# NUC2201AE_v1 register map
File version: 1.0
Registers are 32-bit, read-write, reset 0x0 unless marked. A register's access mark holds for its fields unless they carry their own. Offsets are from the block's base; [hi:lo] are bit positions; {n}, {i} and the like mark numbered series.

## GCR — GCR Register Map
Base 0x50000000
0x00 PDID ro reset 0x20140018 — Part Device Identification Number Register
  [31:0] PDID — Part Device Identification Number. This register reflects device part number code. Software can read this register to identify which device is used.
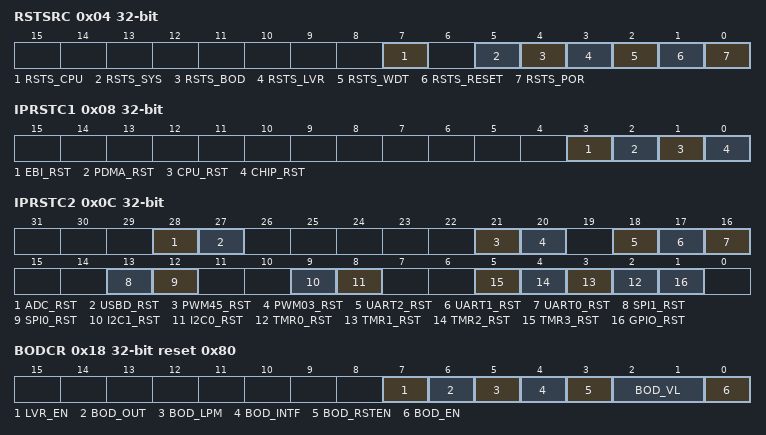
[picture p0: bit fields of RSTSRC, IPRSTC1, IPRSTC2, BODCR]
0x04 RSTSRC (reset mask 0xFFFFFF00) — System Reset Source Register
  [7] RSTS_CPU — CPU Reset Flag. The RSTS_CPU flag Is set by hardware if software writes CPU_RST (IPRSTC1[1]) 1 To reset Cortex-M0 kernel and flash memory controller (FMC). Note: Write 1 to clear this bit to 0.
    0=No reset from CPU; 1=Cortex-M0 CPU kernel and FMC are reset by software setting CPU_RST(IPRSTC1[1]) to 1
  [5] RSTS_SYS — SYS Reset Flag. The RSTS_SYS flag Is set by the 'Reset Signal' from the Cortex-M0 kernel to indicate the previous reset source. Note: Write 1 to clear this bit to 0.
    0=No reset from Cortex-M0; 1=The Cortex-M0 had issued the reset signal to reset the system by writing 1 to bit SYSRESETREQ (AIRCR[2], Application Interrupt and Reset Control Register, address = 0xE000ED0C) in system control registers of Cortex-M0 kernel
  [4] RSTS_BOD — Brown-Out Detector Reset Flag. The RSTS_BOD flag is set by the 'Reset Signal' from the Brown-Out Detector to indicate the previous reset source. Note: Write 1 to clear this bit to 0.
    0=No reset from BOD; 1=The BOD had issued the reset signal to reset the system
  [3] RSTS_LVR — Low Voltage Reset Flag. The RSTS_LVR flag is set by the 'Reset Signal' from the Low-Voltage-Reset controller to indicate the previous reset source. Note: Write 1 to clear this bit to 0.
    0=No reset from LVR; 1=The LVR controller had issued the reset signal to reset the system
  [2] RSTS_WDT — Watchdog Timer Reset Flag. The RSTS_WDT flag is set by the 'Reset Signal' from the watchdog timer or window watchdog timer to indicate the previous reset source. Note1: Write 1 to clear this bit to 0. Note2: Watchdog Timer register WTRF(WTCR[2]) bit is set if the system has been reset by WDT time-out reset. Window Watchdog Timer register WWDTRF(WWDTSR) bit is set if the system has been reset by WWDT time-out reset.
    0=No reset from watchdog timer or window watchdog timer; 1=The watchdog timer or window watchdog timer had issued the reset signal to reset the system
  [1] RSTS_RESET — Reset Pin Reset Flag. The RSTS_RESET flag is set by the 'Reset Signal' from the nRESET Pin to indicate the previous reset source. Note: Write 1 to clear this bit to 0.
    0=No reset from nRESET pin; 1=The Pin nRESET had issued the reset signal to reset the system
  [0] RSTS_POR — Power-On Reset Flag. The RSTS_POR Flag is set by the 'Reset Signal' from the Power-On Reset (POR) vontroller or bit CHIP_RST (IPRSTC1[0]) to indicate the previous reset source. Note: Write 1 to clear this bit to 0.
    0=No reset from POR or CHIP_RST (IPRSTC1[0]); 1=Power-on Reset (POR) or CHIP_RST (IPRSTC1[0]) had issued the reset signal to reset the system
0x08 IPRSTC1 — Peripheral Reset Control Register 1
  [3] EBI_RST — EBI Controller Reset (Write-protection Bit). Set this bit to 1 will generate a reset signal to the EBI. User need to set this bit to 0 to release from the reset state. This bit is the protected bit, It means programming this bit needs to write '59h', '16h', '88h' to address 0x5000_0100 to disable register protection. Refer to the register REGWRPROT at address GCR_BA+0x100
    0=EBI controller normal operation; 1=EBI controller reset
  [2] PDMA_RST — PDMA Controller Reset (Write Protect). Setting this bit to 1 will generate a reset signal to the PDMA. User needs to set this bit to 0 to release from reset state. Note1: This bit is the protected bit, and programming it needs to write '59h', '16h', and '88h' to address 0x5000_0100 to disable register protection. Refer to the register REGWRPROT at address GCR_BA+0x100. Note2: Setting PDMA_RST bit to 1 will generate asynchronous reset signal to PDMA module. Users need to set PDMA_RST to 0 to release PDMA module from reset state.
    0=PDMA controller normal operation; 1=PDMA controller reset
  [1] CPU_RST — CPU Kernel One-Shot Reset (Write Protect). Setting this bit will only reset the CPU kernel and Flash Memory Controller(FMC), and this bit will automatically return 0 after the two clock cycles. Note: This bit is the protected bit, and programming it needs to write '59h', '16h', and '88h' to address 0x5000_0100 to disable register protection. Refer to the register REGWRPROT at address GCR_BA+0x100.
    0=CPU normal operation; 1=CPU one-shot reset
  [0] CHIP_RST — CHIP One-Shot Reset (Write Protect). Setting this bit will reset the whole chip, including CPU kernel and all peripherals, and this bit will automatically return to 0 after the 2 clock cycles. The CHIP_RST is the same as the POR reset, all the chip controllers are reset and the chip setting from flash are also reload. For the difference between CHIP_RST and SYSRESETREQ, please refer to section 5.2.2. Note: This bit is the protected bit, and programming it needs to write '59h', '16h', and '88h' to address 0x5000_0100 to disable register protection. Refer to the register REGWRPROT at address GCR_BA+0x100.
    0=CHIP normal operation; 1=CHIP one-shot reset
0x0C IPRSTC2 — Peripheral Reset Control Register 2
  [28] ADC_RST — ADC Controller Reset
    0=ADC controller normal operation; 1=ADC controller reset
  [27] USBD_RST — USB Device Controller Reset
    0=USB device controller normal operation; 1=USB device controller reset
  [21] PWM45_RST — PWM45 Controller Reset
    0=PWM45 controller normal operation; 1=PWM45 controller reset
  [20] PWM03_RST — PWM03 Controller Reset
    0=PWM03 controller normal operation; 1=PWM03 controller reset
  [18] UART2_RST — UART2 Controller Reset
    0=UART2 controller normal operation; 1=UART2 controller reset
  [17] UART1_RST — UART1 Controller Reset
    0=UART1 controller normal operation; 1=UART1 controller reset
  [16] UART0_RST — UART0 Controller Reset
    0=UART0 controller normal operation; 1=UART0 controller reset
  [13] SPI1_RST — SPI1 Controller Reset
    0=SPI1 controller normal operation; 1=SPI1 controller reset
  [12] SPI0_RST — SPI0 Controller Reset
    0=SPI0 controller normal operation; 1=SPI0 controller reset
  [9] I2C1_RST — I2C1 Controller Reset
    0=I2C1 controller normal operation; 1=I2C1 controller reset
  [8] I2C0_RST — I2C0 Controller Reset
    0=I2C0 controller normal operation; 1=I2C0 controller reset
  [n+2] TMR{n}_RST (n=0..3) — Timer{n} Controller Reset
    0=Timer{n} controller normal operation; 1=Timer{n} controller reset
  [1] GPIO_RST — GPIO Controller Reset
    0=GPIO controller normal operation; 1=GPIO controller reset
0x18 BODCR reset 0x80 (reset mask 0xFFFFFFF0) — Brown-out Detector Control Register
  [7] LVR_EN — Low Voltage Reset Enable Bit (Write Protect). The LVR function reset the chip when the input power voltage is lower than LVR circuit setting. LVR function is enabled by default. Note: This bit is the protected bit, and programming it needs to write '59h', '16h', and '88h' to address 0x5000_0100 to disable register protection. Refer to the register REGWRPROT at address GCR_BA+0x100.
    0=Low Voltage Reset function Disabled; 1=Low Voltage Reset function Enabled - After enabling the bit, the LVR function will be active with 100us delay for LVR output stable (default)
  [6] BOD_OUT — Brown-Out Detector Output Status
    0=Brown-out Detector output status is 0. It means the detected voltage is higher than BOD_VL setting or BOD_EN is 0; 1=Brown-out Detector output status is 1. It means the detected voltage is lower than BOD_VL setting. If the BOD_EN is 0, BOD function disabled, this bit always responds to 0
  [5] BOD_LPM — Brown-Out Detector Low Power Mode (Write Protect). Note1: The BOD consumes about 100 uA in Normal mode, and the low power mode can reduce the current to about 1/10 but slow the BOD response. Note2: This bit is the protected bit, and programming it needs to write '59h', '16h', and '88h' to address 0x5000_0100 to disable register protection. Refer to the register REGWRPROT at address GCR_BA+0x100.
    0=BOD operated in Normal mode (default); 1=BOD Low Power mode Enabled
  [4] BOD_INTF — Brown-Out Detector Interrupt Flag. Note: Write 1 to clear this bit to 0.
    0=Brown-out Detector does not detect any voltage draft at VDD down through or up through the voltage of BOD_VL setting; 1=When Brown-out Detector detects the VDD is dropped down through the voltage of BOD_VL setting or the VDD is raised up through the voltage of BOD_VL setting, this bit is set to 1 and the Brown-out interrupt is requested if Brown-out interrupt is enabled
  [3] BOD_RSTEN — Brown-Out Reset Enable Bit (Write Protect). While the Brown-out Detector function is enabled (BOD_EN high) and BOD reset function is enabled (BOD_RSTEN high), BOD will assert a signal to reset chip when the detected voltage is lower than the threshold (BOD_OUT high). Note1: While the BOD function is enabled (BOD_EN high) and BOD interrupt function is enabled (BOD_RSTEN low), BOD will assert an interrupt if BOD_OUT is high. BOD interrupt will keep till to the BOD_EN set to 0. BOD interrupt can be blocked by disabling the NVIC BOD interrupt or disabling BOD function (set BOD_EN low). Note2: The default value is set by flash controller user configuration register CBORST(CONFIG0[20]) bit. Note3: This bit is the protected bit. It means programming this needs to write '59h', '16h', '88h' to address 0x5000_0100 to disable register protection. Refer to the register REGWRPROT at address GCR_BA+0x100.
    0=Brown-out 'INTERRUPT' function Enabled; 1=Brown-out 'RESET' function Enabled
  [2:1] BOD_VL — Brown-Out Detector Threshold Voltage Selection (Write Protect). The default value is set by flash momory controller user configuration register CBOV(CONFIG0[22:21]) bit . Note: This bit is the protected bit. It means programming this needs to write '59h', '16h', '88h' to address 0x5000_0100 to disable register protection. Refer to the register REGWRPROT at address GCR_BA+0x100.
    0=Brown-out voltage is 2.2V; 1=Brown-out voltage is 2.7V; 2=Brown-out voltage is 3.7V; 3=Brown-out voltage is 4.4V
  [0] BOD_EN — Brown-Out Detector Enable Bit (Write Protect). The default value is set by flash memory controller user configuration register CBODEN(CONFIG0[23]) bit. Note: This bit is the protected bit. It means programming this needs to write '59h', '16h', '88h' to address 0x5000_0100 to disable register protection. Refer to the register REGWRPROT at address GCR_BA+0x100.
    0=Brown-out Detector function Disabled; 1=Brown-out Detector function Enabled
0x1C TEMPCR — Temperature Sensor Control Register
  [0] VTEMP_EN — Temperature Sensor Enable Bit. This bit is used to enable/disable temperature sensor function. Note: After this bit is set to 1, the value of temperature can be obtained from ADC conversion result by ADC channel selecting channel 7 and alternative multiplexer channel selecting temperature sensor. Please refer to the ADC function chapter for detail ADC conversion functional description.
    0=Temperature sensor function Disabled (default); 1=Temperature sensor function Enabled
0x24 PORCR (reset mask 0xFFFF0000) — Power-on-reset Controller Register
  [15:0] POR_DIS_CODE — Power-On-Reset Enable Bit (Write Protect). When powered on, the POR circuit generates a reset signal to reset the whole chip function, but noise on the power may cause the POR active again. User can disable internal POR circuit to avoid unpredictable noise to cause chip reset by writing 0x5AA5 to this field. The POR function will be active again when this field is set to another value or chip is reset by other reset source, including: nRESET, Watchdog Timer reset, Window Watchdog Timer reset, LVR reset, BOD reset, ICE reset command and the software-chip reset function. Note: This bit is the protected bit. It means programming this needs to write '59h', '16h', '88h' to address 0x5000_0100 to disable register protection. Refer to the register REGWRPROT at address GCR_BA+0x100.
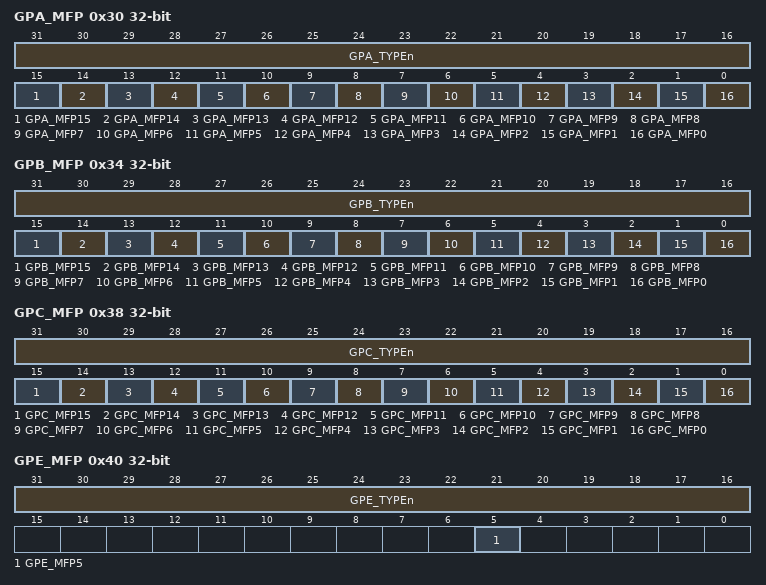
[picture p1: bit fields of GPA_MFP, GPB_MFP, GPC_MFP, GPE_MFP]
0x30 GPA_MFP — GPIOA Multiple Function and Input Type Control Register
  [31:16] GPA_TYPEn — Trigger Function Selection
    0=GPIOA[15:0] I/O input Schmitt Trigger function Disabled; 1=GPIOA[15:0] I/O input Schmitt Trigger function Enabled
  [15] GPA_MFP15 — PA.15 Pin Function Selection
    0=GPIOA function is selected; 1=PWM3 function is selected
  [14] GPA_MFP14 — PA.14 Pin Function Selection. Bits EBI_HB_EN[7] (ALT_MFP[23]), EBI_EN (ALT_MFP[11]) and GPA_MFP[14] determine the PA.14 function. (EBI_HB_EN, EBI_EN, GPA_MFP14) value and function mapping is as following list.
  [13] GPA_MFP13 — PA.13 Pin Function Selection. Bits EBI_HB_EN[6] (ALT_MFP[22]), EBI_EN (ALT_MFP[11]) and GPA_MFP[13] determine the PA.13 function. (EBI_HB_EN, EBI_EN, GPA_MFP13) value and function mapping is as following list.
  [12] GPA_MFP12 — PA.12 Pin Function Selection. Bits EBI_HB_EN[5] (ALT_MFP[21]), EBI_EN (ALT_MFP[11]) and GPA_MFP[12] determine the PA.12 function. (EBI_HB_EN, EBI_EN, GPA_MFP12) value and function mapping is as following list.
  [11] GPA_MFP11 — PA.11 Pin Function Selection. Bits EBI_EN (ALT_MFP[11]) and GPA_MFP[11] determine the PA.11 function. (EBI_EN, GPA_MFP11) value and function mapping is as following list.
  [10] GPA_MFP10 — PA.10 Pin Function Selection. Bits EBI_EN (ALT_MFP[11]) and GPA_MFP[10] determine the PA.10 function. (EBI_EN, GPA_MFP10) value and function mapping is as following list.
  [9] GPA_MFP9 — PA.9 Pin Function Selection. Bit GPA_MFP[9] determines the PA.9 function.
    0=GPIO function is selected; 1=I2C0_SCL function is selected
  [8] GPA_MFP8 — PA.8 Pin Function Selection. Bit GPA_MFP[8] determines the PA.9 function.
    0=GPIO function is selected to the pin PA.8; 1=I2C0_SDA function is selected to the pin PA.8
  [7] GPA_MFP7 — Reserved.
  [6] GPA_MFP6 — PA.6 Pin Function Selection. Bits EBI_EN (ALT_MFP[11]) and GPA_MFP[6] determine the PA.6 function. (EBI_EN, GPA_MFP6) value and function mapping is as following list.
  [5] GPA_MFP5 — PA.5 Pin Function Selection. Bits EBI_HB_EN[0] (ALT_MFP[16]), EBI_EN (ALT_MFP[11]) and GPA_MFP[5] determine the PA.5 function. (EBI_HB_EN, EBI_EN, GPA_MFP5) value and function mapping is as following list,
  [4] GPA_MFP4 — PA.4 Pin Function Selection. Bits EBI_HB_EN[1] (ALT_MFP[17]), EBI_EN (ALT_MFP[11]) and GPA_MFP[4] determine the PA.4 function. (EBI_HB_EN, EBI_EN, GPA_MFP4) value and function mapping is as following list.
  [3] GPA_MFP3 — PA.3 Pin Function Selection. Bits EBI_HB_EN[2] (ALT_MFP[18]), EBI_EN (ALT_MFP[11]) and GPA_MFP[3] determine the PA.3 function. (EBI_HB_EN, EBI_EN, GPA_MFP3) value and function mapping is as following list.
  [2] GPA_MFP2 — PA.2 Pin Function Selection. Bits EBI_HB_EN[3] (ALT_MFP[19]), EBI_EN (ALT_MFP[11]) and GPA_MFP[2] determine the PA.2 function. (EBI_HB_EN, EBI_EN, GPA_MFP2) value and function mapping is as following list.
  [1] GPA_MFP1 — PA.1 Pin Function Selection. Bit EBI_HB_EN[4] (ALT_MFP[20]), EBI_EN (ALT_MFP[11]) and GPA_MFP[1] determine the PA.1 function. (EBI_HB_EN, EBI_EN, GPA_MFP1) value and function mapping is as following list.
  [0] GPA_MFP0 — PA.0 Pin Function Selection
    0=GPIO function is selected; 1=ADC0 function is selected
0x34 GPB_MFP — GPIOB Multiple Function and Input Type Control Register
  [31:16] GPB_TYPEn — Trigger Function Selection
    0=GPIOB[15:0] I/O input Schmitt Trigger function Disabled; 1=GPIOB[15:0] I/O input Schmitt Trigger function Enabled
  [15] GPB_MFP15 — PB.15 Pin Function Selection. Bits PB14_15_EBI (ALT_MFP2[1]), PB15_T0EX (ALT_MFP[24]), PB15_TM0 (ALT_MFP2[2]) and GPB_MFP[15] determine the PB.15 function. (PB14_15_EBI, PB15_T0EX, PB15_TM0, GPB_MFP15) value and function mapping is as following list.
  [14] GPB_MFP14 — PB.14 Pin Function Selection. Bits PB14_15_EBI (ALT_MFP2[1]) and GPB_MFP[14] determine the PB.14 function. (PB14_15_EBI, GPB_MFP14) value and function mapping is as following list
  [13] GPB_MFP13 — PB.13 Pin Function Selection
    0=GPIO function is selected to the pin PB.13; 1=AD1 function is selected
  [12] GPB_MFP12 — Reserved.
  [11] GPB_MFP11 — PB.11 Pin Function Selection. Bits PB11_PWM4 (ALT_MFP[4]) and GPB_MFP[11] determine the PB.11 function. (PB11_PWM4, GPB_MFP11) value and function mapping is as following list.
  [10] GPB_MFP10 — PB.10 Pin Function Selection. Bits PB10_S01 (ALT_MFP[0]) and GPB_MFP[10] determine the PB.10 function. (PB10_S01, GPB_MFP10) value and function mapping is as following list.
  [9] GPB_MFP9 — PB.9 Pin Function Selection. Bits PB9_S11 (ALT_MFP[1]) and GPB_MFP[9] determine the PB.9 function. (PB9_S11, GPB_MFP9) value and function mapping is as following list.
  [8] GPB_MFP8 — PB.8 Pin Function Selection. Bits PB8_CLKO (ALT_MFP[29]) and GPB_MFP[8] determine the PB.8 function. (PB8_CLKO, GPB_MFP8) value and function mapping is as following list.
  [7] GPB_MFP7 — PB.7 Pin Function Selection. Bit EBI_EN (ALT_MFP[11]), GPB_MFP[7] determines the PB.7 function. (EBI_EN, GPB_MFP7) value and function mapping is as following list.
  [6] GPB_MFP6 — PB.6 Pin Function Selection. Bit EBI_EN (ALT_MFP[11]), GPB_MFP[6] determines the PB.6 function. (EBI_EN, GPB_MFP6) value and function mapping is as following list.
  [5] GPB_MFP5 — PB 5 Pin Function Selection. Bit GPB_MFP[5] determines the PB.5 function.
    0=GPIO function is selected to the pin PB.5; 1=UART1_TXD function is selected to the pin PB.5
  [4] GPB_MFP4 — PB.4 Pin Function Selection. Bit GPB_MFP[4] determines the PB.4 function.
    0=GPIO function is selected to the pin PB.4; 1=UART1_RXD function is selected to the pin PB.4
  [3] GPB_MFP3 — PB.3 Pin Function Selection. Bits EBI_nWRH_EN (ALT_MFP[14]), EBI_EN (ALT_MFP[11]), PB3_TM3 (ALT_MFP2[5]), PB3_T3EX (ALT_MFP[27]) and GPB_MFP[3] determine the PB.3 function. (EBI_nWRH_EN, EBI_EN, PB3_TM3, PB3_T3EX, GPB_MFP3) value and function mapping is as following list.
  [2] GPB_MFP2 — PB.2 Pin Function Selection. Bits EBI_nWRL_EN (ALT_MFP[13]), EBI_EN (ALT_MFP[11]), PB2_TM2 (ALT_MFP2[4]), PB2_T2EX (ALT_MFP[26]) and GPB_MFP[2] determine the PB.2 function. (EBI_nWRL_EN, EBI_EN, PB2_TM2, PB2_T2EX, GPB_MFP2) value and function mapping is as following list.
  [1] GPB_MFP1 — PB.1 Pin Function Selection. Bit GPB_MFP[1] determines the PB.1 function.
    0=GPIO function is selected to the pin PB.1; 1=UART0_TXD function is selected to the pin PB.1
  [0] GPB_MFP0 — PB.0 Pin Function Selection. Bit GPB_MFP[0] determines the PB.0 function.
    0=GPIO function is selected to the pin PB.0; 1=UART0_RXD function is selected to the pin PB.0
0x38 GPC_MFP — GPIOC Multiple Function and Input Type Control Register
  [31:16] GPC_TYPEn — Trigger Function Selection
    0=GPIOC[15:0] I/O input Schmitt Trigger function Disabled; 1=GPIOC[15:0] I/O input Schmitt Trigger function Enabled
  [15] GPC_MFP15 — PC.15 Pin Function Selection. Bits EBI_EN (ALT_MFP[11]) and GPC_MFP[15] determine the PC.15 function. (EBI_EN, GPC_MFP15) value and function mapping is as following list
  [14] GPC_MFP14 — PC.14 Pin Function Selection. Bits EBI_EN (ALT_MFP[11]) and GPC_MFP[14] determine the PC.14 function. (EBI_EN, GPC_MFP14) value and function mapping is as following list
  [13] GPC_MFP13 — Reserved.
  [12] GPC_MFP12 — Reserved.
  [11] GPC_MFP11 — PC.11 Pin Function Selection. Bit GPC_MFP[11] determines the PC.11 function.
    0=GPIO function is selected to the pin PC.11; 1=SPI1_MOSI0 function is selected to the pin PC.11
  [10] GPC_MFP10 — PC.10 Pin Function Selection. Bit GPC_MFP[10] determines the PC.10 function.
    0=GPIO function is selected to the pin PC.10; 1=SPI1_MISO0 function is selected to the pin PC.10
  [9] GPC_MFP9 — PC.9 Pin Function Selection. Bit GPC_MFP[9] determines the PC.9 function.
    0=GPIO function is selected to the pin PC.9; 1=SPI1_CLK function is selected to the pin PC.9
  [8] GPC_MFP8 — PC.8 Pin Function Selection. Bits EBI_MCLK_EN (ALT_MFP[12]), EBI_EN (ALT_MFP[11]), GPC_MFP[8] determine the PC.8 function. (EBI_MCLK_EN, EBI_EN, GPC_MFP8) value and function mapping is as following list.
  [7] GPC_MFP7 — PC.7 Pin Function Selection. Bits EBI_EN (ALT_MFP[11]) and GPC_MFP[7] determine the PC.7 function. (EBI_EN, GPC_MFP7) value and function mapping is as following list.
  [6] GPC_MFP6 — PC.6 Pin Function Selection. Bits EBI_EN (ALT_MFP[11]) and GPC_MFP[6] determine the PC.6 function. (EBI_EN, GPB_MFP6) value and function mapping is as following list.
  [5] GPC_MFP5 — Reserved.
  [4] GPC_MFP4 — Reserved.
  [3] GPC_MFP3 — PC.3 Pin Function Selection
    0=GPIO function is selected; 1=SPI0_MOSI0 function is selected
  [2] GPC_MFP2 — PC.2 Pin Function Selection
    0=GPIO function is selected; 1=SPI0_MISO0 function is selected
  [1] GPC_MFP1 — PC.1 Pin Function Selection
    0=GPIO function is selected; 1=SPI0_CLK function is selected
  [0] GPC_MFP0 — PC.0 Pin Function Selection
    0=GPIO function is selected; 1=SPI0_SS0 function is selected
0x40 GPE_MFP — GPIOE Multiple Function and Input Type Control Register
  [31:16] GPE_TYPEn — Trigger Function Selection
    0=GPIOE[15:0] I/O input Schmitt Trigger function Disabled; 1=GPIOE[15:0] I/O input Schmitt Trigger function Enabled
  [5] GPE_MFP5 — PE.5 Pin Function Selection. Bits PE5_T1EX (ALT_MFP[25]), PE5_TM1 (ALT_MFP2[3]) and GPE_MFP5 determine the PE.5 function. (PE5_T1EX, PE5_TM1, GPE_MFP5) value and function mapping is as following list.
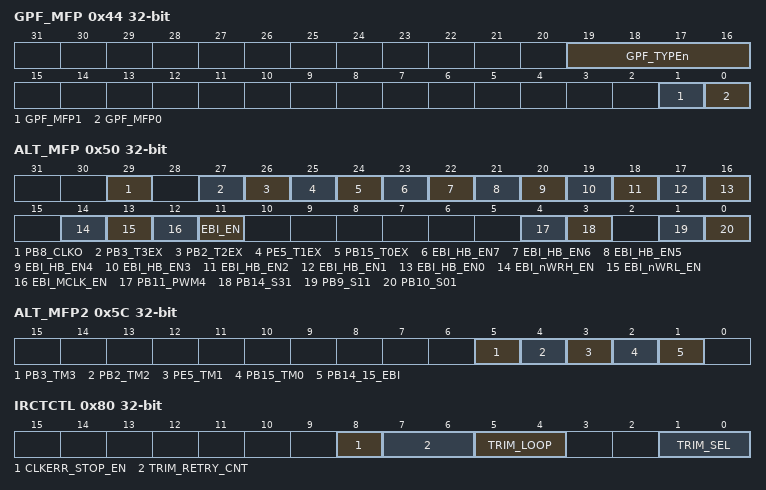
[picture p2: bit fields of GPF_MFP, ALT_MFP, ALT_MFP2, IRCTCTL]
0x44 GPF_MFP (reset mask 0xFFFFFFF0) — GPIOF Multiple Function and Input Type Control Register
  [19:16] GPF_TYPEn — Trigger Function Selection
    0=GPIOF[3:0] I/O input Schmitt Trigger function Disabled; 1=GPIOF[3:0] I/O input Schmitt Trigger function Enabled
  [1] GPF_MFP1 — PF.1 Pin Function Selection. Bit GPF_MFP[1] determines the PF.1 function. Note: This bit is read only and is decided by user configuration CGPFMFP (CONFIG0[27]).
    0=GPIO function is selected to the pin PF.1; 1=XT1_IN function is selected to the pin PF.1
  [0] GPF_MFP0 — PF.0 Pin Function Selection. Bit GPF_MFP[0] determines the PF.0 function. Note: This bit is read only and is decided by user configuration CGPFMFP (CONFIG0[27]).
    0=GPIO function is selected to the pin PF.0; 1=XT1_OUT function is selected to the pin PF.0
0x50 ALT_MFP — Alternative Multiple Function Pin Control Register
  [29] PB8_CLKO — PB.8 Pin Alternative Function Selection. Bits PB8_CLKO (ALT_MFP[29]) and GPB_MFP[8] determine the PB.8 function. (PB8_CLKO, GPB_MFP8) value and function mapping is as following list.
  [27] PB3_T3EX — PB.3 Pin Alternative Function Selection. Bits EBI_nWRH_EN (ALT_MFP[14]), EBI_EN (ALT_MFP[11]), PB3_TM3 (ALT_MFP2[5]), PB3_T3EX (ALT_MFP[27]) and GPB_MFP[3] determine the PB.3 function. (EBI_nWRH_EN, EBI_EN, PB3_TM3, PB3_T3EX, GPB_MFP3) value and function mapping is as following list.
  [26] PB2_T2EX — PB.2 Pin Alternative Function Selection. Bits EBI_nWRL_EN (ALT_MFP[13]), EBI_EN (ALT_MFP[11]), PB2_TM2 (ALT_MFP2[4]), PB2_T2EX (ALT_MFP[26]) and GPB_MFP[2] determine the PB.2 function. (EBI_nWRL_EN, EBI_EN, PB2_TM2, PB2_T2EX, GPB_MFP2) value and function mapping is as following list.
  [25] PE5_T1EX — PE.5 Pin Alternative Function Selection. Bits PE5_T1EX (ALT_MFP[25]), PE5_TM1 (ALT_MFP2[3]) and GPE_MFP5 determine the PE.5 function. (PE5_T1EX, PE5_TM1, GPE_MFP5) value and function mapping is as following list.
  [24] PB15_T0EX — PB.15 Pin Alternative Function Selection. Bits PB14_15_EBI (ALT_MFP2[1]), PB15_T0EX (ALT_MFP[24]), PB15_TM0 (ALT_MFP2[2]) and GPB_MFP[15] determine the PB.15 function. (PB14_15_EBI, PB15_T0EX, PB15_TM0, GPB_MFP15) value and function mapping is as following list.
  [23] EBI_HB_EN7 — Bits EBI_HB_EN[7] (ALT_MFP[23]), EBI_EN (ALT_MFP[11]) and GPA_MFP[14] determine the PA.14 function. (EBI_HB_EN, EBI_EN, GPA_MFP14) value and function mapping is as following list.
  [22] EBI_HB_EN6 — Bits EBI_HB_EN[6] (ALT_MFP[22]), EBI_EN (ALT_MFP[11]) and GPA_MFP[13] determine the PA.13 function. (EBI_HB_EN, EBI_EN, GPA_MFP13) value and function mapping is as following list.
  [21] EBI_HB_EN5 — Bits EBI_HB_EN[5] (ALT_MFP[21]), EBI_EN (ALT_MFP[11]) and GPA_MFP[12] determine the PA.12 function. (EBI_HB_EN, EBI_EN, GPA_MFP12) value and function mapping is as following list.
  [20] EBI_HB_EN4 — Bit EBI_HB_EN[4] (ALT_MFP[20]), EBI_EN (ALT_MFP[11]) and GPA_MFP[1] determine the PA.1 function. (EBI_HB_EN, EBI_EN, GPA_MFP1) value and function mapping is as following list.
  [19] EBI_HB_EN3 — Bits EBI_HB_EN[3] (ALT_MFP[19]), EBI_EN (ALT_MFP[11]) and GPA_MFP[2] determine the PA.2 function. (EBI_HB_EN, EBI_EN, GPA_MFP2) value and function mapping is as following list.
  [18] EBI_HB_EN2 — Bits EBI_HB_EN[2] (ALT_MFP[18]), EBI_EN (ALT_MFP[11]) and GPA_MFP[3] determine the PA.3 function. (EBI_HB_EN, EBI_EN, GPA_MFP3) value and function mapping is as following list.
  [17] EBI_HB_EN1 — Bits EBI_HB_EN[1] (ALT_MFP[17]), EBI_EN (ALT_MFP[11]) and GPA_MFP[4] determine the PA.4 function. (EBI_HB_EN, EBI_EN, GPA_MFP4) value and function mapping is as following list.
  [16] EBI_HB_EN0 — Bits EBI_HB_EN[0] (ALT_MFP[16]), EBI_EN (ALT_MFP[11]) and GPA_MFP[5] determine the PA.5 function. (EBI_HB_EN, EBI_EN, GPA_MFP5) value and function mapping is as following list,
  [14] EBI_nWRH_EN — Bits EBI_nWRH_EN (ALT_MFP[14]), EBI_EN (ALT_MFP[11]), PB3_TM3 (ALT_MFP2[5]), PB3_T3EX (ALT_MFP[27]) and GPB_MFP[3] determine the PB.3 function. (EBI_nWRH_EN, EBI_EN, PB3_TM3, PB3_T3EX, GPB_MFP3) value and function mapping is as following list.
  [13] EBI_nWRL_EN — Bits EBI_nWRL_EN (ALT_MFP[13]), EBI_EN (ALT_MFP[11]), PB2_TM2 (ALT_MFP2[4]), PB2_T2EX (ALT_MFP[26]) and GPB_MFP[2] determine the PB.2 function. (EBI_nWRL_EN, EBI_EN, PB2_TM2, PB2_T2EX, GPB_MFP2) value and function mapping is as following list.
  [12] EBI_MCLK_EN — Bits EBI_MCLK_EN (ALT_MFP[12]), EBI_EN (ALT_MFP[11]), GPC_MFP[8] determine the PC.8 function. (EBI_MCLK_EN, EBI_EN, GPC_MFP8) value and function mapping is as following list.
  [11] EBI_EN — EBI_EN is use to switch GPIO function to EBI function (AD[15:0], ALE, RE, WE, CS, MCLK), it need additional registers EBI_EN[7:0] and EBI_MCLK_EN for some GPIO to switch to EBI function(AD[15:8], MCLK)
  [4] PB11_PWM4 — PB.11 Pin Alternative Function Selection. Bits PB11_PWM4 (ALT_MFP[4]) and GPB_MFP[11] determine the PB.11 function. (PB11_PWM4, GPB_MFP11) value and function mapping is as following list.
  [3] PB14_S31 — PB.14 Pin Alternative Function Selection. Bits PB14_15_EBI (ALT_MFP2[1]) and GPB_MFP[14] determine the PB.14 function. (PB14_15_EBI, GPB_MFP14) value and function mapping is as following list
  [1] PB9_S11 — PB.9 Pin Alternative Function Selection. Bits PB9_S11 (ALT_MFP[1]) and GPB_MFP[9] determine the PB.9 function. (PB9_S11, GPB_MFP9) value and function mapping is as following list.
  [0] PB10_S01 — PB.10 Pin Alternative Function Selection. Bits PB10_S01 (ALT_MFP[0]) and GPB_MFP[10] determine the PB.10 function. (PB10_S01, GPB_MFP10) value and function mapping is as following list.
0x5C ALT_MFP2 — Alternative Multiple Function Pin Control Register 2
  [5] PB3_TM3 — PB.3 Pin Alternative Function Selection. Bits EBI_nWRH_EN (ALT_MFP[14]), EBI_EN (ALT_MFP[11]), PB3_TM3 (ALT_MFP2[5]), PB3_T3EX (ALT_MFP[27]) and GPB_MFP[3] determine the PB.3 function. (EBI_nWRH_EN, EBI_EN, PB3_TM3, PB3_T3EX, GPB_MFP3) value and function mapping is as following list.
  [4] PB2_TM2 — PB.2 Pin Alternative Function Selection. Bits EBI_nWRL_EN (ALT_MFP[13]), EBI_EN (ALT_MFP[11]), PB2_TM2 (ALT_MFP2[4]), PB2_T2EX (ALT_MFP[26]) and GPB_MFP[2] determine the PB.2 function. (EBI_nWRL_EN, EBI_EN, PB2_TM2, PB2_T2EX, GPB_MFP2) value and function mapping is as following list.
  [3] PE5_TM1 — PE.5 Pin Alternative Function Selection. Bits PE5_T1EX (ALT_MFP[25]), PE5_TM1 (ALT_MFP2[3]) and GPE_MFP5 determine the PE.5 function. (PE5_T1EX, PE5_TM1, GPE_MFP5) value and function mapping is as following list.
  [2] PB15_TM0 — PB.15 Pin Alternative Function Selection. Bits PB14_15_EBI (ALT_MFP2[1]), PB15_T0EX (ALT_MFP[24]), PB15_TM0 (ALT_MFP2[2]) and GPB_MFP[15] determine the PB.15 function. (PB14_15_EBI, PB15_T0EX, PB15_TM0, GPB_MFP15) value and function mapping is as following list.
  [1] PB14_15_EBI — PB .14 and PB.15 Pin Alternative Function Selection. Bits PB14_15_EBI (ALT_MFP2[1]), PB15_T0EX (ALT_MFP[24]), PB15_TM0 (ALT_MFP2[2]) and GPB_MFP[15] determine the PB.15 function. (PB14_15_EBI, PB15_T0EX, PB15_TM0, GPB_MFP15) value and function mapping is as following list.
0x80 IRCTCTL — IRC Trim Control Register
  [8] CLKERR_STOP_EN — Clock Error Stop Enable Bit
    0=The trim operation is kept going if clock is inaccuracy; 1=The trim operation is stopped if clock is inaccuracy
  [7:6] TRIM_RETRY_CNT — Trim Value Update Limitation Count. The field defines that how many times of HIRC trim value is updated by auto trim circuit before the HIRC frequency locked. Once the HIRC locked, the internal trim value update counter will be reset. If the trim value update counter reached this limitation value and frequency of HIRC still doesn't lock, the auto trim operation will be disabled and TRIM_SEL will be cleared to 00.
    0=Trim retry count limitation is 64; 1=Trim retry count limitation is 128; 2=Trim retry count limitation is 256; 3=Trim retry count limitation is 512
  [5:4] TRIM_LOOP — Trim Calculation Loop. This field defines that trim value calculation is based on how many 32.768 kHz clocks in. For example, if TRIM_LOOP is set as 00, auto trim circuit will calculate trim value based on the average frequency difference in 4 32.768 kHz clock.
    0=Trim value calculation is based on average difference in 4 clocks; 1=Trim value calculation is based on average difference in 8 clocks; 2=Trim value calculation is based on average difference in 16 clocks; 3=Trim value calculation is based on average difference in 32 clocks
  [1:0] TRIM_SEL — Trim Frequency Selection. This field indicates the target frequency of internal 22.1184 MHz high speed oscillator will trim to precise 22.1184MHz or 24MHz automatically. If no any target frequency is selected (TRIM_SEL is 00), the HIRC auto trim function is disabled. During auto trim operation, if clock error detected because of CLKERR_STOP_EN is set to 1 or trim retry limitation counts reached, this field will be cleared to 00 automatically.
    0=HIRC auto trim function Disabled; 1=HIRC auto trim function Enabled and HIRC trimmed to 22.1184 MHz; 2=HIRC auto trim function Enabled and HIRC trimmed to 24 MHz
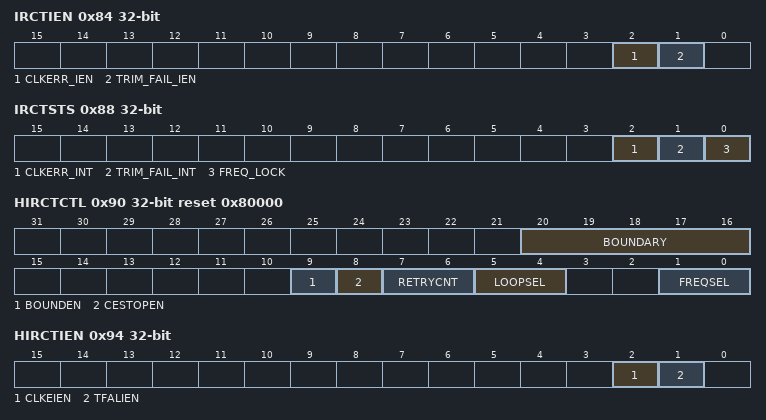
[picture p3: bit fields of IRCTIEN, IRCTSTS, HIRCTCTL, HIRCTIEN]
0x84 IRCTIEN — IRC Trim Interrupt Enable Register
  [2] CLKERR_IEN — Clock Error Interrupt Enable Bit. This bit controls if CPU would get an interrupt while clock is inaccuracy during auto trim operation. If this bit is set to1, and CLKERR_INT (IRCTRIMINT[2]) is set during auto trim operation. An interrupt will be triggered to notify the clock frequency is inaccuracy.
    0=CLKERR_INT (IRCTRIMINT[2]) status to trigger an interrupt to CPU Disabled; 1=CLKERR_INT (IRCTRIMINT[2]) status to trigger an interrupt to CPU Enabled
  [1] TRIM_FAIL_IEN — Trim Failure Interrupt Enable Bit. This bit controls if an interrupt will be triggered while HIRC trim value update limitation count reached and HIRC frequency still not locked on target frequency set by TRIM_SEL (IRCTCTL[1:0]). If this bit is high and TRIM_FAIL_INT (IRCTRIMINT[1]) is set during auto trim operation. An interrupt will be triggered to notify that HIRC trim value update limitation count was reached.
    0=TRIM_FAIL_INT (IRCTRIMINT[1]) status to trigger an interrupt to CPU Disabled; 1=TRIM_FAIL_INT (IRCTRIMINT[1]) status to trigger an interrupt to CPU Enabled
0x88 IRCTSTS — IRC Trim Interrupt Status Register
  [2] CLKERR_INT — Clock Error Interrupt Status. When the frequency of external 32.768 kHz low speed crystal or internal 22.1184 MHz high speed oscillator is shift larger to unreasonable value, this bit will be set and to be an indicate that clock frequency is inaccuracy. Once this bit is set to 1, the auto trim operation stopped and TRIM_SEL (IRCTCTL[1:0]) will be cleared to 00 by hardware automatically if CLKERR_STOP_EN (IRCTCTL[8]) is set to 1. If this bit is set and CLKERR_IEN (IRCTIEN [2]) is high, an interrupt will be triggered to notify the clock frequency is inaccuracy. Write 1 to clear this to 0.
    0=Clock frequency is accurate; 1=Clock frequency is inaccurate
  [1] TRIM_FAIL_INT — Trim Failure Interrupt Status. This bit indicates that internal 22.1184 MHz high speed oscillator trim value update limitation count reached and the internal 22.1184 MHz high speed oscillator clock frequency still doesn't be locked. Once this bit is set, the auto trim operation stopped and TRIM_SEL (IRCTCTL[1:0]) will be cleared to 00 by hardware automatically. If this bit is set and TRIM_FAIL_IEN (IRCTIEN[1]) is high, an interrupt will be triggered to notify that HIRC trim value update limitation count was reached. Write 1 to clear this to 0.
    0=Trim value update limitation count did not reach; 1=Trim value update limitation count reached and internal 22.1184 MHz high speed oscillator frequency was still not locked
  [0] FREQ_LOCK — HIRC Frequency Lock Status. This bit indicates the internal 22.1184 MHz high speed oscillator frequency is locked. This is a status bit and doesn't trigger any interrupt.
0x90 HIRCTCTL reset 0x80000 — HIRC Trim Control Register
  [20:16] BOUNDARY — Boundary Selection. Fill the boundary range from 1 to 31, 0 is reserved. Note: This field is effective only when the BOUNDEN(SYS_HIRCTCTL[9]) is enable.
  [9] BOUNDEN — Boundary Enable
    0=Boundary function is disable; 1=Boundary function is enable
  [8] CESTOPEN — Clock Error Stop Enable Bit
    0=The trim operation is keep going if clock is inaccuracy; 1=The trim operation is stopped if clock is inaccuracy
  [7:6] RETRYCNT — Trim Value Update Limitation Count. This field defines that how many times the auto trim circuit will try to update the HIRC trim value before the frequency of HIRC locked. Once the HIRC locked, the internal trim value update counter will be reset. If the trim value update counter reached this limitation value and frequency of HIRC still doesn't lock, the auto trim operation will be disabled and FREQSEL will be cleared to 00.
    0=Trim retry count limitation is 64 loops; 1=Trim retry count limitation is 128 loops; 2=Trim retry count limitation is 256 loops; 3=Trim retry count limitation is 512 loops
  [5:4] LOOPSEL — Trim Calculation Loop Selection. This field defines that trim value calculation is based on how many reference clocks. Note: For example, if LOOPSEL is set as 00, auto trim circuit will calculate trim value based on the average frequency difference in 4 clocks of reference clock.
    0=Trim value calculation is based on average difference in 4 clocks of reference clock; 1=Trim value calculation is based on average difference in 8 clocks of reference clock; 2=Trim value calculation is based on average difference in 16 clocks of reference clock; 3=Trim value calculation is based on average difference in 32 clocks of reference clock
  [1:0] FREQSEL — Trim Frequency Selection. This field indicates the target frequency of 48 MHz internal high speed RC oscillator (HIRC) auto trim. During auto trim operation, if clock error detected with CESTOPEN is set to 1 or trim retry limitation count reached, this field will be cleared to 00 automatically.
    0=Disable HIRC auto trim function; 1=Enable HIRC auto trim function and trim HIRC to 48 MHz
0x94 HIRCTIEN — HIRC Trim Interrupt Enable Register
  [2] CLKEIEN — Clock Error Interrupt Enable Bit. This bit controls if CPU would get an interrupt while clock is inaccuracy during auto trim operation. If this bit is set to1, and CLKERRIF(SYS_HIRCTSTS[2]) is set during auto trim operation, an interrupt will be triggered to notify the clock frequency is inaccuracy.
    0=Disable CLKERRIF(SYS_HIRCTSTS[2]) status to trigger an interrupt to CPU; 1=Enable CLKERRIF(SYS_HIRCTSTS[2]) status to trigger an interrupt to CPU
  [1] TFALIEN — Trim Failure Interrupt Enable Bit. This bit controls if an interrupt will be triggered while HIRC trim value update limitation count reached and HIRC frequency still not locked on target frequency set by FREQSEL(SYS_HIRCTCTL[1:0]). If this bit is high and TFAILIF(SYS_HIRCTSTS[1]) is set during auto trim operation, an interrupt will be triggered to notify that HIRC trim value update limitation count was reached.
    0=Disable TFAILIF(SYS_HIRCTSTS[1]) status to trigger an interrupt to CPU; 1=Enable TFAILIF(SYS_HIRCTSTS[1]) status to trigger an interrupt to CPU
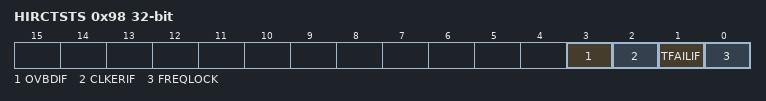
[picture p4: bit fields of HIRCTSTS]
0x98 HIRCTSTS — HIRC Trim Interrupt Status Register
  [3] OVBDIF — Over Boundary Status. When the over boundary function is set, if there occurs the over boundary condition, this flag will be set. Note: Write 1 to clear this flag.
    0=Over boundary coundition did not occur; 1=Over boundary coundition occurred
  [2] CLKERIF — Clock Error Interrupt Status. When the reference clock or 48MHz internal high speed RC oscillator (HIRC) is shift larger to unreasonable value, this bit will be set and to be an indicate that clock frequency is inaccuracy. Once this bit is set to 1, the auto trim operation stopped and FREQSEL(SYS_HIRCTCTL[1:0]) will be cleared to 00 by hardware automatically if CESTOPEN(SYS_HIRCTCTL[8]) is set to 1. If this bit is set and CLKEIEN(SYS_HIRCTIEN[2]) is high, an interrupt will be triggered to notify the clock frequency is inaccuracy. Write 1 to clear this to 0. Note : reset by powr on reset
    0=Clock frequency is accuracy; 1=Clock frequency is inaccuracy
  [1] TFAILIF — Trim Failure Interrupt Status. This bit indicates that HIRC trim value update limitation count reached and the HIRC clock frequency still doesn't be locked. Once this bit is set, the auto trim operation stopped and FREQSEL(SYS_HIRCTCTL[1:0]) will be cleared to 00 by hardware automatically. If this bit is set and TFAILIEN(SYS_HIRCTIEN[1]) is high, an interrupt will be triggered to notify that HIRC trim value update limitation count was reached. Write 1 to clear this to 0. Note : reset by powr on reset
    0=Trim value update limitation count does not reach; 1=Trim value update limitation count reached and HIRC frequency still not locked
  [0] FREQLOCK — HIRC Frequency Lock Status. This bit indicates the HIRC frequency is locked. This is a status bit and doesn't trigger any interrupt. Write 1 to clear this to 0. This bit will be set automatically, if the frequecy is lock and the RC_TRIM is enabled. Note : reset by powr on reset
    0=The internal high-speed oscillator frequency doesn't lock at 48 MHz yet; 1=The internal high-speed oscillator frequency locked at 48 MHz
0x100 REGWRPROT — Register Write Protection Register
  [7:0] REGWRPROT — Register Write-Protection Code (Write Only). Some registers have write-protection function. Writing these registers have to disable the protected function by writing the sequence value '59h', '16h', '88h' to this field. After this sequence is completed, the REGPROTDIS bit will be set to 1 and write-protection registers can be normal write. Register Write-Protection Disable Index (Read Only). The Protected registers are: IPRSTC1: address 0x5000_0008. BODCR: address 0x5000_0018. PORCR: address 0x5000_0024. PWRCON: address 0x5000_0200 (bit[6] is not protected for power wake-up interrupt clear). APBCLK bit[0]: address 0x5000_0208 (bit[0] is Watchdog Timer clock enable). CLKSEL0: address 0x5000_0210 (for HCLK and CPU STCLK clock source selection). CLKSEL1 bit[1:0]: address 0x5000_0214 (for Watchdog Timer clock source selection). NMI_SEL bit[8]: address 0x5000_0380 (for NMI_EN interrupt enable). ISPCON: address 0x5000_C000 (Flash ISP Control register). ISPTRG: address 0x5000_C010 (ISP Trigger Control register). WTCR: address 0x4000_4000. FATCON: address 0x5000_C018. Note: The bits which are write-protected will be noted as' (Write Protect)' beside the description.
    0=Write-protection is enabled for writing protected registers. Any write to the protected register is ignored; 1=Write-protection is disabled for writing protected registers
